# WS53 register map
File version: 0.1.0-experimental
Registers are 32-bit, read-write, no defined reset value unless marked. A register's access mark holds for its fields unless they carry their own. Offsets are from the block's base; [hi:lo] are bit positions; {n}, {i} and the like mark numbered series; 'fields as' and 'values as' point back to an identical list.

## QSPI1
Base 0x5208D000
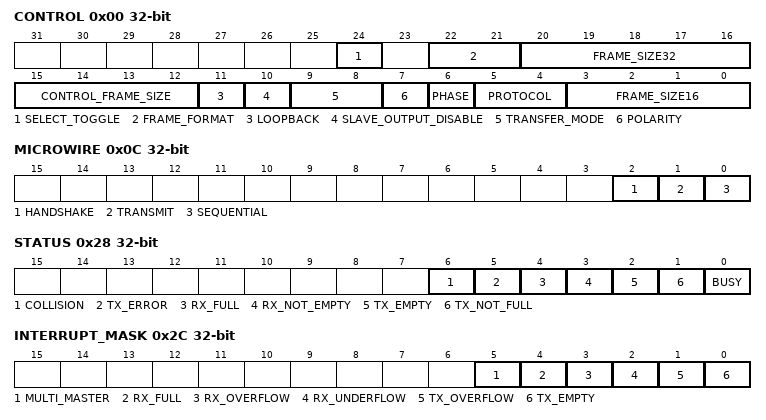
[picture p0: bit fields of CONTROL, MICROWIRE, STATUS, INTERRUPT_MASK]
0x00 CONTROL
  [24] SELECT_TOGGLE, [22:21] FRAME_FORMAT, [20:16] FRAME_SIZE32, [15:12] CONTROL_FRAME_SIZE, [11] LOOPBACK, [10] SLAVE_OUTPUT_DISABLE, [9:8] TRANSFER_MODE, [7] POLARITY, [6] PHASE, [5:4] PROTOCOL, [3:0] FRAME_SIZE16
0x04 FRAME_COUNT
  [15:0] VALUE
0x08 ENABLE
  [0] START
0x0C MICROWIRE
  [2] HANDSHAKE, [1] TRANSMIT, [0] SEQUENTIAL
0x10 SLAVE_ENABLE
  [15:0] VALUE
0x14 BAUD
  [15:0] VALUE — SDK header: even divider 2..65534, bit0 fixed zero; zero disables SCK. Setter truncates to 16 bits and does not round; silicon behavior unverified
0x18 TX_THRESHOLD
  [31:0] VALUE
0x1C RX_THRESHOLD
  [31:0] VALUE
0x20 TX_LEVEL ro
  [31:0] VALUE
0x24 RX_LEVEL ro
  [31:0] VALUE
0x28 STATUS ro read-modifies
  [6] COLLISION read-clears — SDK sr_data_t: master collision status clears on read. Relation to RAW_INTERRUPT acknowledgement is not established; do not use STATUS as an IRQ acknowledgement. SDK documentation, not silicon-qualified.
  [5] TX_ERROR read-clears — SDK sr_data_t: transmit FIFO empty when a slave transfer starts; clears on read. Only a slave can set this flag; the WS53 QSPI1 port is master-only. This is not TX FIFO overflow. SDK documentation, not silicon-qualified.
  [4] RX_FULL
  [3] RX_NOT_EMPTY
  [2] TX_EMPTY
  [1] TX_NOT_FULL
  [0] BUSY
0x2C INTERRUPT_MASK
  [5] MULTI_MASTER, [4] RX_FULL, [3] RX_OVERFLOW, [2] RX_UNDERFLOW, [1] TX_OVERFLOW, [0] TX_EMPTY
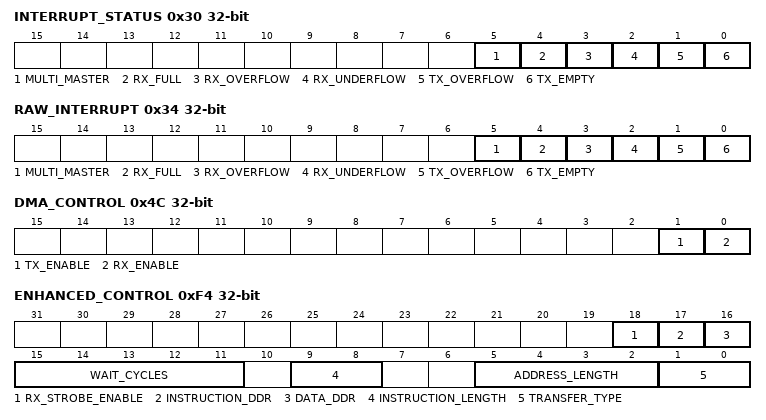
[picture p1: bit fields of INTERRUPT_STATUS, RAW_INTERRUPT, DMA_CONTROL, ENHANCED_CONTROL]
0x30 INTERRUPT_STATUS ro
  fields as INTERRUPT_MASK
0x34 RAW_INTERRUPT ro
  fields as INTERRUPT_MASK
0x38 CLEAR_TX_OVERFLOW ro read-clears
  [0] CLEAR read-clears — Read acknowledges the corresponding interrupt; writes have no effect
0x3C CLEAR_RX_OVERFLOW ro read-clears
  fields as CLEAR_TX_OVERFLOW
0x40 CLEAR_RX_UNDERFLOW ro read-clears
  fields as CLEAR_TX_OVERFLOW
0x44 CLEAR_MULTI_MASTER ro read-clears
  fields as CLEAR_TX_OVERFLOW
0x48 CLEAR_ALL ro read-clears
  fields as CLEAR_TX_OVERFLOW
0x4C DMA_CONTROL
  [1] TX_ENABLE, [0] RX_ENABLE
0x50 DMA_TX_LEVEL
  [31:0] VALUE
0x54 DMA_RX_LEVEL
  [31:0] VALUE
0x58 IDENTIFICATION ro
  [31:0] VALUE
0x5C VERSION ro
  [31:0] VALUE
{0x60+4i} RX[{i}] (i=0..35) ro read-has-side-effects
  [31:0] DATA read-has-side-effects — Pop one received frame from the shared RX FIFO, regardless of window index
{0x60+4i} TX[{i}] (i=0..35) wo (alternate view of RX[{i}])
  [31:0] DATA — Push one frame into the shared TX FIFO, regardless of window index
0xF0 RX_SAMPLE_DELAY
  [7:0] VALUE
0xF4 ENHANCED_CONTROL
  [18] RX_STROBE_ENABLE, [17] INSTRUCTION_DDR, [16] DATA_DDR, [15:11] WAIT_CYCLES, [9:8] INSTRUCTION_LENGTH, [5:2] ADDRESS_LENGTH, [1:0] TRANSFER_TYPE
0xF8 TX_DRIVE_EDGE
  [7:0] VALUE

## FAMA_STATUS
Base 0x5208F800
{0x0+4i} SOURCE[{i}] (i=0..3) ro
  [31:0] PAGE — Source first address shifted right12
{0x20+4i} END[{i}] (i=0..3) ro
  [31:0] PAGE — Source inclusive last address shifted right12
{0x40+4i} DESTINATION[{i}] (i=0..3) ro
  [31:0] DELTA — Two's-complement destination minus source page number

## GLB_CTL
Base 0x57000000
0x48 UART_L0_IRQ_ROUTE_COMMAND wo — UART L0 interrupt routing command view: SDK writes the complete word 1 to route only to acore; other values and physical read behavior unverified
  [31:0] ACORE_ONLY range 1..1
0xB0 UART_SOFT_RESET 16-bit
  [7] UART_L0_RESET_N — UART L0/application UART2 reset, active low; preserve all other bits
0xC8 SDIO_SOFT_RESET — SDK SDIO reset patch control; pulse does not establish bus-master drain
  [1] SDIO_RESET_N — SDK drives low then high; preserve other bits. No reset-state or self-clear inference

## TCXO
Base 0x57000200
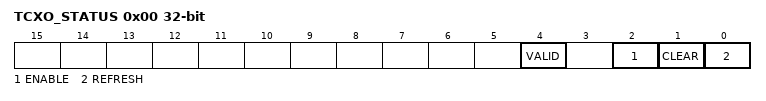
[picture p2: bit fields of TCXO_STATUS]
0x00 TCXO_STATUS access per field
  [4] VALID ro — TCXO count value valid flag
  [2] ENABLE rw — TCXO count enable: 1=enable counting
  [1] CLEAR rw — TCXO count clear: 1=clear counter
  [0] REFRESH rw — TCXO count refresh: 1=trigger count latch
{0x4+4i} TCXO_COUNT{i} ro (i=0..3)
  [15:0] COUNT{i} — Counter value bits [{16i+15}:{16i}]
